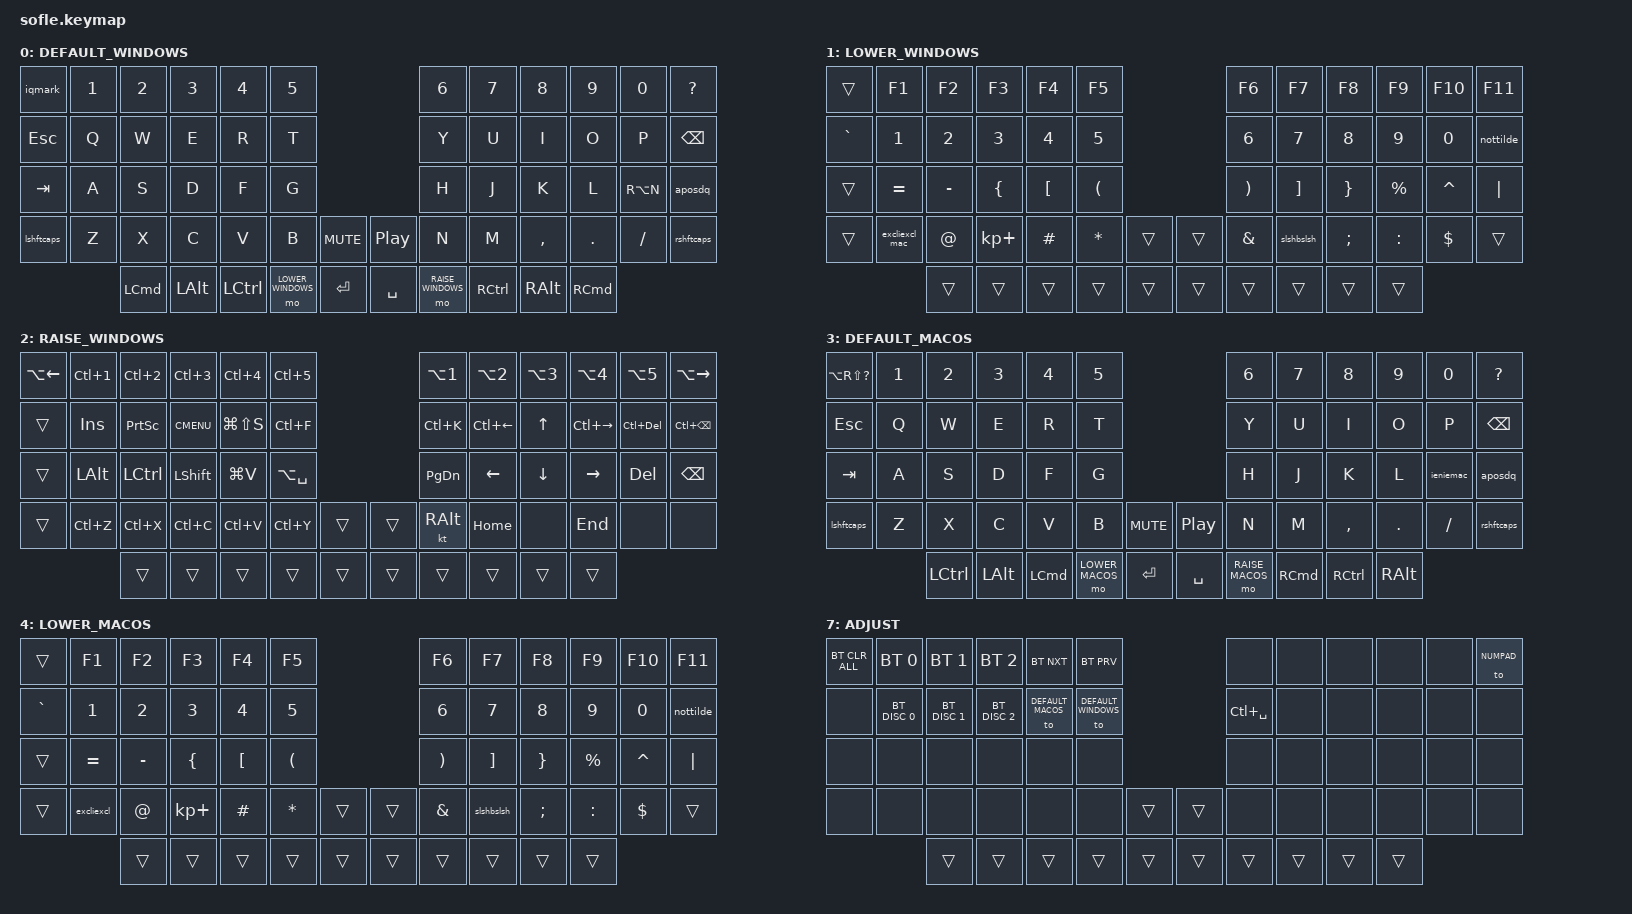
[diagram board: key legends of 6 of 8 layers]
/*
 * Copyright (c) 2020 The ZMK Contributors
 *
 * SPDX-License-Identifier: MIT
 */

#include <behaviors.dtsi>
#include <dt-bindings/zmk/keys.h>
#include <dt-bindings/zmk/bt.h>

&mt {
    tapping-term-ms = <200>;
};

#define DEFAULT_WINDOWS 0
#define LOWER_WINDOWS 1
#define RAISE_WINDOWS 2

#define DEFAULT_MACOS 3
#define LOWER_MACOS 4
#define RAISE_MACOS 5

#define NUMPAD 6

#define ADJUST 7


/ {
    
    conditional_layers {
        compatible = "zmk,conditional-layers";
        adjust_layer_windows {
            if-layers = <LOWER_WINDOWS RAISE_WINDOWS>;
            then-layer = <ADJUST>;
        };
        
        adjust_layer_macos {
            if-layers = <LOWER_MACOS RAISE_MACOS>;
            then-layer = <ADJUST>;
        };
    };

    macros {
        //ascii code for ! is ALT+0173
        iexc: iexc {
            compatible = "zmk,behavior-macro";
            #binding-cells = <0>;
            wait-ms = <0>;
            tap-ms = <0>;
            bindings
                = 
                <&macro_press   &kp LALT>
                , <&macro_tap &kp KP_N1 &kp KP_N7 &kp KP_N3>
                , <&macro_release &kp LALT>;
        };
        //ascii code for ! on mac is ALT+1
        iexc_mac: iexc_mac {
            compatible = "zmk,behavior-macro";
            #binding-cells = <0>;
            wait-ms = <0>;
            tap-ms = <0>;
            bindings
                = 
                <&macro_press   &kp LALT>
                , <&macro_tap &kp KP_N1>
                , <&macro_release &kp LALT>;
        };
        //ascii code for ? is ALT+0167
        iqmark: iqmark {
            compatible = "zmk,behavior-macro";
            #binding-cells = <0>;
            wait-ms = <0>;
            tap-ms = <0>;
            bindings
                =
                <&macro_press   &kp LALT>
                , <&macro_tap &kp KP_N1 &kp KP_N6 &kp KP_N8>
                , <&macro_release &kp LALT>;
        };
        //ascii code for ñ is ALT+0241
        ieniemac: ieniemac {
            compatible = "zmk,behavior-macro";
            #binding-cells = <0>;
            wait-ms = <0>;
            tap-ms = <0>;
            bindings
                =
                <&macro_press   &kp LALT>
                , <&macro_tap &kp N>
                , <&macro_release &kp LALT>,
                <&macro_tap &kp N>;
        };
    };

    behaviors {
        //left shift y capslock
        lshftcaps: lshftcaps {
            compatible = "zmk,behavior-tap-dance";
            #binding-cells = <0>;
            tapping-term-ms = <200>;
            bindings = <&kp LSHFT>, <&kp CAPSLOCK>;
        };
        //right shift y capslock
        rshftcaps: rshftcaps {
            compatible = "zmk,behavior-tap-dance";
            #binding-cells = <0>;
            tapping-term-ms = <200>;
            bindings = <&kp RSHFT>, <&kp CAPSLOCK>;
        };
        //double quote apostrophe
        aposdq: aposdq {
            compatible = "zmk,behavior-tap-dance";
            #binding-cells = <0>;
            tapping-term-ms = <200>;
            bindings = <&kp SQT>, <&kp LS(SQT)>;
        };
        //exclamation mark i exclamation mark
        excliexcl: excliexcl {
            compatible = "zmk,behavior-tap-dance";
            #binding-cells = <0>;
            tapping-term-ms = <200>;
            bindings = <&kp EXCL>, <&iexc>;
        };
        //exclamation mark i exclamation mark mac
        excliexcl_mac:  excliexcl_mac {
            compatible = "zmk,behavior-tap-dance";
            #binding-cells = <0>;
            tapping-term-ms = <200>;
            bindings = <&kp EXCL>, <&iexc_mac>;
        };
        //slash backslash
        slshbslsh: slshbslsh {
            compatible = "zmk,behavior-tap-dance";
            #binding-cells = <0>;
            tapping-term-ms = <200>;
            bindings = <&kp SLASH>, <&kp BSLH>;
        };
        //tilde backslash
        nottilde: nottilde {
            compatible = "zmk,behavior-tap-dance";
            #binding-cells = <0>;
            tapping-term-ms = <200>;
            bindings = <&kp TILDE>, <&kp RA(BSLH)>;
        };

    };

    keymap {
        compatible = "zmk,keymap";
        DEFAULT_WINDOWS {
            bindings = < 
&iqmark  &kp N1 &kp N2   &kp N3   &kp N4    &kp N5                      &kp N6 &kp N7    &kp N8    &kp N9   &kp N0   &kp QMARK
&kp ESC   &kp Q  &kp W    &kp E    &kp R     &kp T                       &kp Y  &kp U     &kp I     &kp O    &kp P    &kp BSPC
&kp TAB   &kp A  &kp S    &kp D    &kp F     &kp G                       &kp H  &kp J     &kp K     &kp L    &kp RA(N)     &aposdq
&lshftcaps &kp Z  &kp X    &kp C    &kp V     &kp B  &kp C_MUTE &kp C_PP     &kp N  &kp M     &kp COMMA &kp DOT  &kp FSLH &rshftcaps
                &kp LCMD &kp LALT &kp LCTRL &mo LOWER_WINDOWS  &kp RET    &kp SPACE &mo RAISE_WINDOWS  &kp RCTRL &kp RALT  &kp RCMD
            >;

            sensor-bindings = <&inc_dec_kp C_VOL_UP C_VOL_DN &inc_dec_kp PG_UP PG_DN>;
        };

        LOWER_WINDOWS {
            bindings = <
&trans    &kp F1    &kp F2    &kp F3      &kp F4    &kp F5                    &kp F6    &kp F7   &kp F8          &kp F9    &kp F10   &kp F11
&kp GRAVE &kp N1    &kp N2    &kp N3      &kp N4    &kp N5                    &kp N6    &kp N7   &kp N8          &kp N9    &kp N0    &nottilde
&trans    &kp EQUAL  &kp MINUS    &kp LBRC    &kp LBKT  &kp LPAR                 &kp RPAR &kp RBKT &kp RBRC &kp PERCENT  &kp CARET  &kp PIPE
&trans    &excliexcl_mac &kp AT &kp KP_PLUS &kp HASH  &kp ASTRK  &trans   &trans &kp AMPS  &slshbslsh &kp SEMICOLON  &kp COLON &kp DLLR  &trans
                    &trans    &trans      &trans    &trans    &trans   &trans &trans    &trans   &trans          &trans
            >;

            sensor-bindings = <&inc_dec_kp C_VOL_UP C_VOL_DN &inc_dec_kp PG_UP PG_DN>;
        };

        RAISE_WINDOWS {
            bindings = <
&kp LA(LEFT) &kp LC(N1) &kp LC(N2) &kp LC(N3) &kp LC(N4) &kp LC(N5)                         &kp LA(N1) &kp LA(N2) &kp LA(N3) &kp LA(N4) &kp LA(N5) &kp LA(RIGHT)
&trans     &kp INS      &kp PSCRN    &kp K_CMENU  &kp LG(LS(S)) &kp LC(F)                   &kp LC(K) &kp LC(LEFT)    &kp UP   &kp LC(RIGHT)    &kp LC(DEL)   &kp LC(BSPC)
&trans     &kp LALT     &kp LCTRL    &kp LSHFT    &kp LG(V)     &kp LA(SPACE)                   &kp PG_DN &kp LEFT  &kp DOWN &kp RIGHT &kp DEL &kp BSPC
&trans     &kp LC(Z)   &kp LC(X)    &kp LC(C)   &kp LC(V)  &kp LC(Y)  &trans        &trans  &kt RIGHT_ALT    &kp HOME    &none   &kp END     &none  &none
                        &trans       &trans       &trans       &trans  &trans   &trans  &trans    &trans    &trans   &trans
            >;
            sensor-bindings = <&inc_dec_kp C_VOL_UP C_VOL_DN &inc_dec_kp PG_UP PG_DN>;
        };

        DEFAULT_MACOS {
            bindings = < 
&kp LA(RS(QMARK))  &kp N1 &kp N2   &kp N3   &kp N4    &kp N5                      &kp N6 &kp N7    &kp N8    &kp N9   &kp N0   &kp QMARK
&kp ESC   &kp Q  &kp W    &kp E    &kp R     &kp T                       &kp Y  &kp U     &kp I     &kp O    &kp P    &kp BSPC
&kp TAB   &kp A  &kp S    &kp D    &kp F     &kp G                       &kp H  &kp J     &kp K     &kp L    &ieniemac    &aposdq
&lshftcaps &kp Z  &kp X    &kp C    &kp V     &kp B  &kp C_MUTE &kp C_PP     &kp N  &kp M     &kp COMMA &kp DOT  &kp FSLH &rshftcaps
                &kp LCTRL &kp LALT &kp LCMD &mo LOWER_MACOS  &kp RET    &kp SPACE &mo RAISE_MACOS  &kp RCMD  &kp RCTRL &kp RALT
            >;

            sensor-bindings = <&inc_dec_kp C_VOL_UP C_VOL_DN &inc_dec_kp PG_UP PG_DN>;
        };
    
        LOWER_MACOS {
            bindings = <
&trans    &kp F1    &kp F2    &kp F3      &kp F4    &kp F5                    &kp F6    &kp F7   &kp F8          &kp F9    &kp F10   &kp F11
&kp GRAVE &kp N1    &kp N2    &kp N3      &kp N4    &kp N5                    &kp N6    &kp N7   &kp N8          &kp N9    &kp N0    &nottilde
&trans    &kp EQUAL  &kp MINUS    &kp LBRC    &kp LBKT  &kp LPAR                 &kp RPAR &kp RBKT &kp RBRC &kp PERCENT  &kp CARET  &kp PIPE
&trans    &excliexcl &kp AT &kp KP_PLUS &kp HASH  &kp ASTRK  &trans   &trans &kp AMPS  &slshbslsh &kp SEMICOLON  &kp COLON &kp DLLR  &trans
                    &trans    &trans      &trans    &trans    &trans   &trans &trans    &trans   &trans          &trans
            >;
            sensor-bindings = <&inc_dec_kp C_VOL_UP C_VOL_DN &inc_dec_kp PG_UP PG_DN>;
        };

        RAISE_MACOS {
        bindings = <
&none  &kp LG(N1) &kp LG(N2) &kp LG(N3)  &kp LG(N4)     &kp LG(N5)                        &kp LC(UP_ARROW) &kp LC(LEFT) &kp LG(GRAVE)     &kp LC(RIGHT) &kp LC(LG(F)) &kp LC(DOWN_ARROW)
&trans &kp INS    &kp PSCRN  &kp K_CMENU &kp LG(LS(N4)) &kp LG(F)                         &kp PG_UP        &kp LA(LEFT) &kp UP            &kp LA(RIGHT) &kp LA(DEL)   &kp LA(BSPC)
&trans &kp LALT   &kp LCMD   &kp LSHFT   &kp LG(A)      &kp LG(SPACE)                     &kp PG_DN        &kp LEFT     &kp DOWN          &kp RIGHT     &kp DEL       &kp BSPC
&trans &kp LG(Z)  &kp LG(X)  &kp LG(C)   &kp LG(V)      &kp LG(S)     &trans      &trans  &kp LCMD         &kp HOME     &kp LS(LG(GRAVE)) &kp END       &none         &trans
                  &trans     &trans      &trans         &trans        &trans      &trans  &trans           &trans       &trans            &trans        &trans
            >;
            sensor-bindings = <&inc_dec_kp C_VOL_UP C_VOL_DN &inc_dec_kp PG_UP PG_DN>;
        };

        NUMPAD {
            bindings = <
&none	&none	&none	&none	&none	&none	                    &kp N7	&kp N8	&kp N9	&kp BSPC	&none	    &to DEFAULT_WINDOWS
&none	&none	&none	&none	&none	&none	                    &kp N4	&kp N5	&kp N6	&kp MINUS	&kp BSLH	&none
&none	&none	&none	&none	&none	&none	                    &kp N1	&kp N2	&kp N3	&kp PLUS	&kp ASTRK	&none
&none	&none	&none	&none	&none	&none	&trans      &trans  &kp N0	&none	&kp DOT	&kp RET	&none	&none
                &trans  &trans  &trans  &trans  &trans      &trans  &trans  &trans  &trans  &trans  &trans
            >;
        };

        ADJUST {
            bindings = <
&bt BT_CLR_ALL  &bt BT_SEL 0  &bt BT_SEL 1  &bt BT_SEL 2    &bt BT_NXT           &bt BT_PRV                    &none           &none    &none    &none    &none    &to NUMPAD
&none           &bt BT_DISC 0 &bt BT_DISC 1 &bt BT_DISC 2   &to DEFAULT_MACOS    &to DEFAULT_WINDOWS           &kp LC(SPACE)   &none    &none    &none    &none    &none
&none           &none         &none         &none           &none                &none                         &none           &none    &none    &none    &none    &none
&none           &none         &none         &none           &none                &none  &trans        &trans   &none           &none    &none    &none    &none    &none
                              &trans       &trans           &trans               &trans  &trans       &trans   &trans          &trans   &trans   &trans
            >;
            sensor-bindings = <&inc_dec_kp C_VOL_UP C_VOL_DN &inc_dec_kp PG_UP PG_DN>;
        };
    };
};
